# LAV_AT_E70ES1 register map
Vendor: Latticsemi.com; Series: LAV-AT; File version: 1.0
Registers are 32-bit, read-write, reset 0x0 unless marked. A register's access mark holds for its fields unless they carry their own. Offsets are from the block's base; [hi:lo] are bit positions.

## tse_mac0_inst
Base 0x40001000
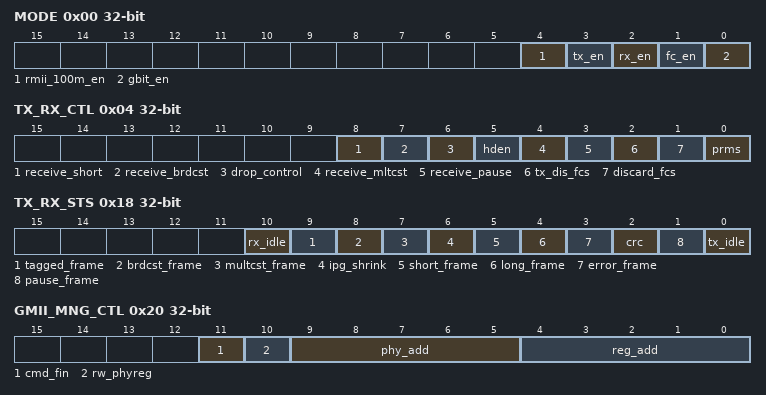
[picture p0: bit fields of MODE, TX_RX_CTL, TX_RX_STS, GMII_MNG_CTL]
0x00 MODE
  [4] rmii_100m_en — RMII speed switch, 1 - 100Mbps, 0 - 10Mbps
  [3] tx_en — Transmit Enable
  [2] rx_en — Receive Enable
  [1] fc_en — Flow-control Enable
  [0] gbit_en — Gbit enable
0x04 TX_RX_CTL
  [8] receive_short — Receive Short Frames
  [7] receive_brdcst — Receive Broadcast
  [6] drop_control
  [5] hden — Half-duplex Enable
  [4] receive_mltcst — Receive Multicast
  [3] receive_pause
  [2] tx_dis_fcs — Transmit Disable FCS
  [1] discard_fcs — Receive Discard FCS and Pad
  [0] prms — Promiscuous Mode
0x08 MAX_PKT_SIZE
  [15:0] max_pkt_size — Maximum Packet Size
0x0C IPG
  [15:0] ipg — Inter-Packet Gap
0x10 MAC_ADDR_0
  [31:0] mac_addr_0 — First 4 Bytes of MAC Address
0x14 MAC_ADDR_1
  [15:0] mac_addr_1 — Last 2 Bytes of MAC Address
0x18 TX_RX_STS
  [10] rx_idle ro — Rx MAC Idle
  [9] tagged_frame ro — Rx tagged frame
  [8] brdcst_frame ro — Rx broadcast frame
  [7] multcst_frame ro — Rx multicast frame
  [6] ipg_shrink ro — Rx shrunk IPG frame(IPG less then 96 bit time)
  [5] short_frame ro — Rx short frame
  [4] long_frame ro — Rx long frame
  [3] error_frame ro — Rx frame error
  [2] crc ro — Rx CRC Error
  [1] pause_frame ro — Rx PAUSE Frame
  [0] tx_idle ro — Tx MAC Idle
0x1C VLAN_TAG
  [15:0] vlan ro — length/type of field of the VLAN tag
0x20 GMII_MNG_CTL
  [11] cmd_fin — Command Finished
  [10] rw_phyreg — Read/Write PHY Registers
  [9:5] phy_add — GMII PHY Address
  [4:0] reg_add — GMII Register Address
0x24 GMII_MNG_DAT
  [15:0] gmii_dat — GMII Management Access Data
0x28 MLT_TAB_0
  [31:0] multicast_table0 — Multicast Table Word 0
0x2C MLT_TAB_1
  [32:0] multicast_table1 — Multicast Table Word 1
0x30 PAUS_OP
  [15:0] pause_opcode
0x34 TX_AFIFO_AFULL_TH
  [10:0] tx_fifo_afull_th — TX FIFO Almost Full Threshold
0x38 TX_AFIFO_AEMPTY_TH
  [10:0] tx_fifo_aempty_th — TX FIFO Almost Empty Threshold
0x3C RX_AFIFO_AFULL_TH
  [10:0] rx_fifo_afull_th — RX FIFO Almost Full Threshold
0x40 RX_AFIFO_AEMPTY_TH
  [10:0] rx_fifo_aempty_th — RX FIFO Almost Empty Threshold
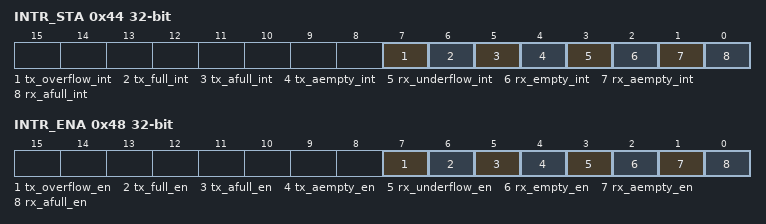
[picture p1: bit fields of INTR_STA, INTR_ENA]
0x44 INTR_STA
  [7] tx_overflow_int — TX FIFO Overflow Interrrupt
  [6] tx_full_int — TX FIFO Full Interrrupt
  [5] tx_afull_int — TX FIFO Almost Full Interrrupt
  [4] tx_aempty_int — TX FIFO Almost Empty Interrrupt
  [3] rx_underflow_int — RX FIFO Underflow Interrupt
  [2] rx_empty_int — RX FIFO Empty Interrupt
  [1] rx_aempty_int — RX FIFO Almost Empty Interrupt
  [0] rx_afull_int — RX FIFO Almost Full Interrupt
0x48 INTR_ENA
  [7] tx_overflow_en — TX FIFO Overflow Interrrupt Enable
  [6] tx_full_en — TX FIFO Full Interrrupt Enable
  [5] tx_afull_en — TX FIFO Almost Full Interrrupt Enable
  [4] tx_aempty_en — TX FIFO Almost Empty Interrrupt Enable
  [3] rx_underflow_en — RX FIFO Underflow Interrupt Enable
  [2] rx_empty_en — RX FIFO Empty Interrupt Enable
  [1] rx_aempty_en — RX FIFO Almost Empty Interrupt Enable
  [0] rx_afull_en — RX FIFO Almost Full Interrupt Enable
0x4C TX_STAT_UNICST_0
  [31:0] tx_stat_unicst_0 ro — empty content
0x50 TX_STAT_UNICST_1
  [31:0] tx_stat_unicst_1 ro — empty content
0x54 TX_STAT_MULTCST_0
  [31:0] tx_stat_multcst_0 ro — empty content
0x58 TX_STAT_MULTCST_1
  [31:0] tx_stat_multcst_1 ro — empty content
0x5C TX_STAT_BRDCST_0
  [31:0] tx_stat_brdcst_0 ro — empty content
0x60 TX_STAT_BRDCST_1
  [31:0] tx_stat_brdcst_1 ro — empty content
0x64 TX_STAT_BADFCS_0
  [31:0] tx_stat_badfcs_0 ro — empty content
0x68 TX_STAT_BADFCS_1
  [31:0] tx_stat_badfcs_1 ro — empty content
0x6C TX_STAT_JMBO_0
  [31:0] tx_stat_jmbo_0 ro — empty content
0x70 TX_STAT_JMBO_1
  [31:0] tx_stat_jmbo_1 ro — empty content
0x74 TX_STAT_UNDER_RUN_0
  [31:0] tx_stat_under_run_0 ro — empty content
0x78 TX_STAT_UNDER_RUN_1
  [31:0] tx_stat_under_run_1 ro — empty content
0x7C TX_STAT_PAUSE_0
  [31:0] tx_stat_pause_0 ro — empty content
0x80 TX_STAT_PAUSE_1
  [31:0] tx_stat_pause_1 ro — empty content
0x84 TX_STAT_VLN_TG_0
  [31:0] tx_stat_vln_tg_0 ro — empty content
0x88 TX_STAT_VLN_TG_1
  [31:0] tx_stat_vln_tg_1 ro — empty content
0x8C TX_STAT_FRM_LNGTH_0
  [31:0] tx_stat_frm_lngth_0 ro — empty content
0x90 TX_STAT_FRM_LNGTH_1
  [31:0] tx_stat_frm_lngth_1 ro — empty content
0x94 TX_STAT_DEFERRED_TRANS_0
  [31:0] tx_stat_deferred_trans_0 ro — empty content
0x98 TX_STAT_DEFERRED_TRANS_1
  [31:0] tx_stat_deferred_trans_1 ro — empty content
0x9C TX_STAT_EXCESSIVE_DEFERRED_TRANS_0
  [31:0] tx_stat_excessive_deferred_trans_0 ro — empty content
0xA0 TX_STAT_EXCESSIVE_DEFERRED_TRANS_1
  [31:0] tx_stat_excessive_deferred_trans_1 ro — empty content
0xA4 TX_STAT_LATE_COL_0
  [31:0] tx_stat_late_col_0 ro — empty content
0xA8 TX_STAT_LATE_COL_1
  [31:0] tx_stat_late_col_1 ro — empty content
0xAC TX_STAT_EXCESSIVE_COL_0
  [31:0] tx_stat_excessive_col_0 ro — empty content
0xB0 TX_STAT_EXCESSIVE_COL_1
  [31:0] tx_stat_excessive_col_1 ro — empty content
0xB4 TX_STAT_NUM_EARLY_COL_0
  [31:0] tx_stat_num_early_col_0 ro — empty content
0xB8 TX_STAT_NUM_EARLY_COL_1
  [31:0] tx_stat_num_early_col_1 ro — empty content
0xBC TX_STAT_SHRT_FRM_DIS_FCS_0
  [31:0] tx_stat_shrt_frm_dis_fcs_0 ro — empty content
0xC0 TX_STAT_SHRT_FRM_DIS_FCS_1
  [31:0] tx_stat_shrt_frm_dis_fcs_1 ro — empty content
0xC4 TX_STAT_PTP1588_FRM_0
  [31:0] tx_stat_ptp1588_frm_0 ro — empty content
0xC8 TX_STAT_PTP1588_FRM_1
  [31:0] tx_stat_ptp1588_frm_1 ro — empty content
0xCC TX_STAT_FRM_64_0
  [31:0] tx_stat_frm_64_0 ro — empty content
0xD0 TX_STAT_FRM_64_1
  [31:0] tx_stat_frm_64_1 ro — empty content
0xD4 TX_STAT_FRM_65_127_0
  [31:0] tx_stat_frm_65_127_0 ro — empty content
0xD8 TX_STAT_FRM_65_127_1
  [31:0] tx_stat_frm_65_127_1 ro — empty content
0xDC TX_STAT_FRM_128_255_0
  [31:0] tx_stat_frm_128_255_0 ro — empty content
0xE0 TX_STAT_FRM_128_255_1
  [31:0] tx_stat_frm_128_255_1 ro — empty content
0xE4 TX_STAT_FRM_256_511_0
  [31:0] tx_stat_frm_256_511_0 ro — empty content
0xE8 TX_STAT_FRM_256_511_1
  [31:0] tx_stat_frm_256_511_1 ro — empty content
0xEC TX_STAT_FRM_512_1023_0
  [31:0] tx_stat_frm_512_1023_0 ro — empty content
0xF0 TX_STAT_FRM_512_1023_1
  [31:0] tx_stat_frm_512_1023_1 ro — empty content
0xF4 TX_STAT_FRM_1024_1518_0
  [31:0] tx_stat_frm_1024_1518_0 ro — empty content
0xF8 TX_STAT_FRM_1024_1518_1
  [31:0] tx_stat_frm_1024_1518_1 ro — empty content
0xFC TX_STAT_FRM_1519_2047_0
  [31:0] tx_stat_frm_1519_2047_0 ro — empty content
0x100 TX_STAT_FRM_1519_2047_1
  [31:0] tx_stat_frm_1519_2047_1 ro — empty content
0x104 TX_STAT_FRM_2048_4095_0
  [31:0] tx_stat_frm_2048_4095_0 ro — empty content
0x108 TX_STAT_FRM_2048_4095_1
  [31:0] tx_stat_frm_2048_4095_1 ro — empty content
0x10C TX_STAT_FRM_4096_9216_0
  [31:0] tx_stat_frm_4096_9216_0 ro — empty content
0x110 TX_STAT_FRM_4096_9216_1
  [31:0] tx_stat_frm_4096_9216_1 ro — empty content
0x114 TX_STAT_FRM_9217_16383_0
  [31:0] tx_stat_frm_9217_16383_0 ro — empty content
0x118 TX_STAT_FRM_9217_16383_1
  [31:0] tx_stat_frm_9217_16383_1 ro — empty content
0x11C RX_STAT_FRM_LNGTH_0
  [31:0] rx_stat_frm_lngth_0 ro — empty content
0x120 RX_STAT_FRM_LNGTH_1
  [31:0] rx_stat_frm_lngth_1 ro — empty content
0x124 RX_STAT_VLN_TG_0
  [31:0] rx_stat_vln_tg_0 ro — empty content
0x128 RX_STAT_VLN_TG_1
  [31:0] rx_stat_vln_tg_1 ro — empty content
0x12C RX_STAT_PAUSE_0
  [31:0] rx_stat_pause_0 ro — empty content
0x130 RX_STAT_PAUSE_1
  [31:0] rx_stat_pause_1 ro — empty content
0x134 RX_STAT_CTRL_0
  [31:0] rx_stat_ctrl_0 ro — empty content
0x138 RX_STAT_CTRL_1
  [31:0] rx_stat_ctrl_1 ro — empty content
0x13C RX_STAT_UNSP_OPCODE_0
  [31:0] rx_stat_unsp_opcode_0 ro — empty content
0x140 RX_STAT_UNSP_OPCODE_1
  [31:0] rx_stat_unsp_opcode_1 ro — empty content
0x144 RX_STAT_DRIBB_NIBB_0
  [31:0] rx_stat_dribb_nibb_0 ro — empty content
0x148 RX_STAT_DRIBB_NIBB_1
  [31:0] rx_stat_dribb_nibb_1 ro — empty content
0x14C RX_STAT_BRDCST_0
  [31:0] rx_stat_brdcst_0 ro — empty content
0x150 RX_STAT_BRDCST_1
  [31:0] rx_stat_brdcst_1 ro — empty content
0x154 RX_STAT_MULTCST_0
  [31:0] rx_stat_multcst_0 ro — empty content
0x158 RX_STAT_MULTCST_1
  [31:0] rx_stat_multcst_1 ro — empty content
0x15C RX_STAT_UNICST_0
  [31:0] rx_stat_unicst_0 ro — empty content
0x160 RX_STAT_UNICST_1
  [31:0] rx_stat_unicst_1 ro — empty content
0x164 RX_STAT_RCVD_OK_0
  [31:0] rx_stat_rcvd_ok_0 ro — empty content
0x168 RX_STAT_RCVD_OK_1
  [31:0] rx_stat_rcvd_ok_1 ro — empty content
0x16C RX_STAT_LNGTH_ERR_0
  [31:0] rx_stat_lngth_err_0 ro — empty content
0x170 RX_STAT_LNGTH_ERR_1
  [31:0] rx_stat_lngth_err_1 ro — empty content
0x174 RX_STAT_CRC_ERR_0
  [31:0] rx_stat_crc_err_0 ro — empty content
0x178 RX_STAT_CRC_ERR_1
  [31:0] rx_stat_crc_err_1 ro — empty content
0x17C RX_STAT_PKT_IGNORE_0
  [31:0] rx_stat_pkt_ignore_0 ro — empty content
0x180 RX_STAT_PKT_IGNORE_1
  [31:0] rx_stat_pkt_ignore_1 ro — empty content
0x184 RX_STAT_PREVIOUS_CARRIER_EVENT_0
  [31:0] rx_stat_previous_carrier_event_0 ro — empty content
0x188 RX_STAT_PREVIOUS_CARRIER_EVENT_1
  [31:0] rx_stat_previous_carrier_event_1 ro — empty content
0x18C RX_STAT_PTP1588_FRM_0
  [31:0] rx_stat_ptp1588_frm_0 ro — empty content
0x190 RX_STAT_PTP1588_FRM_1
  [31:0] rx_stat_ptp1588_frm_1 ro — empty content
0x194 RX_STAT_IPG_VIOL_0
  [31:0] rx_stat_ipg_viol_0 ro — empty content
0x198 RX_STAT_IPG_VIOL_1
  [31:0] rx_stat_ipg_viol_1 ro — empty content
0x19C RX_STAT_SHRT_FRM_0
  [31:0] rx_stat_shrt_frm_0 ro — empty content
0x1A0 RX_STAT_SHRT_FRM_1
  [31:0] rx_stat_shrt_frm_1 ro — empty content
0x1A4 RX_STAT_LNG_FRM_0
  [31:0] rx_stat_lng_frm_0 ro — empty content
0x1A8 RX_STAT_LNG_FRM_1
  [31:0] rx_stat_lng_frm_1 ro — empty content
0x1AC RX_STAT_FRM_UNDERSIZE_0
  [31:0] rx_stat_frm_undersize_0 ro — empty content
0x1B0 RX_STAT_FRM_UNDERSIZE_1
  [31:0] rx_stat_frm_undersize_1 ro — empty content
0x1B4 RX_STAT_FRM_FRAGMENTS_0
  [31:0] rx_stat_frm_fragments_0 ro — empty content
0x1B8 RX_STAT_FRM_FRAGMENTS_1
  [31:0] rx_stat_frm_fragments_1 ro — empty content
0x1BC RX_STAT_FRM_JABBER_0
  [31:0] rx_stat_frm_jabber_0 ro — empty content
0x1C0 RX_STAT_FRM_JABBER_1
  [31:0] rx_stat_frm_jabber_1 ro — empty content
0x1C4 RX_STAT_FRM_64_GOOD_CRC_0
  [31:0] rx_stat_frm_64_good_crc_0 ro — empty content
0x1C8 RX_STAT_FRM_64_GOOD_CRC_1
  [31:0] rx_stat_frm_64_good_crc_1 ro — empty content
0x1CC RX_STAT_FRM_1518_GOOD_CRC_0
  [31:0] rx_stat_frm_1518_good_crc_0 ro — empty content
0x1D0 RX_STAT_FRM_1518_GOOD_CRC_1
  [31:0] rx_stat_frm_1518_good_crc_1 ro — empty content
0x1D4 RX_STAT_FRM_64_0
  [31:0] rx_stat_frm_64_0 ro — empty content
0x1D8 RX_STAT_FRM_64_1
  [31:0] rx_stat_frm_64_1 ro — empty content
0x1DC RX_STAT_FRM_65_127_0
  [31:0] rx_stat_frm_65_127_0 ro — empty content
0x1E0 RX_STAT_FRM_65_127_1
  [31:0] rx_stat_frm_65_127_1 ro — empty content
0x1E4 RX_STAT_FRM_128_255_0
  [31:0] rx_stat_frm_128_255_0 ro — empty content
0x1E8 RX_STAT_FRM_128_255_1
  [31:0] rx_stat_frm_128_255_1 ro — empty content
0x1EC RX_STAT_FRM_256_511_0
  [31:0] rx_stat_frm_256_511_0 ro — empty content
0x1F0 RX_STAT_FRM_256_511_1
  [31:0] rx_stat_frm_256_511_1 ro — empty content
0x1F4 RX_STAT_FRM_512_1023_0
  [31:0] rx_stat_frm_512_1023_0 ro — empty content
0x1F8 RX_STAT_FRM_512_1023_1
  [31:0] rx_stat_frm_512_1023_1 ro — empty content
0x1FC RX_STAT_FRM_1024_1518_0
  [31:0] rx_stat_frm_1024_1518_0 ro — empty content
0x200 RX_STAT_FRM_1024_1518_1
  [31:0] rx_stat_frm_1024_1518_1 ro — empty content
0x204 RX_STAT_FRM_1519_2047_0
  [31:0] rx_stat_frm_1519_2047_0 ro — empty content
0x208 RX_STAT_FRM_1519_2047_1
  [31:0] rx_stat_frm_1519_2047_1 ro — empty content
0x20C RX_STAT_FRM_2048_4095_0
  [31:0] rx_stat_frm_2048_4095_0 ro — empty content
0x210 RX_STAT_FRM_2048_4095_1
  [31:0] rx_stat_frm_2048_4095_1 ro — empty content
0x214 RX_STAT_FRM_4096_9216_0
  [31:0] rx_stat_frm_4096_9216_0 ro — empty content
0x218 RX_STAT_FRM_4096_9216_1
  [31:0] rx_stat_frm_4096_9216_1 ro — empty content
0x21C RX_STAT_FRM_9217_16383_0
  [31:0] rx_stat_frm_9217_16383_0 ro — empty content
0x220 RX_STAT_FRM_9217_16383_1
  [31:0] rx_stat_frm_9217_16383_1 ro — empty content
